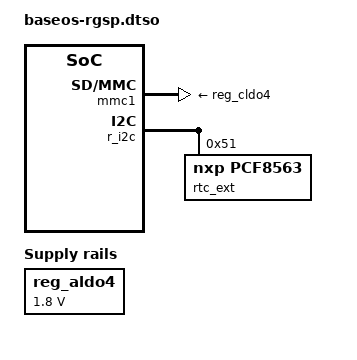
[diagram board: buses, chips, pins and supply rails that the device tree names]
// SPDX-License-Identifier: (GPL-2.0-only OR BSD-2-Clause)
/* The RG SP shares the RG28XX power chip and audio wiring. */
#include "baseos-rg28xx.dtso"

&battery {
    charge-full-design-microamp-hours = <3500000>;
};

&reg_aldo4 {
    regulator-min-microvolt = <1800000>;
    regulator-max-microvolt = <1800000>;
};

&axp717 {
    regulators {
        reg_cldo4: cldo4 {
            regulator-name = "vcc-radio";
            regulator-min-microvolt = <3300000>;
            regulator-max-microvolt = <3300000>;
            /* Bluetooth shares this rail with Wi-Fi. */
            regulator-always-on;
            regulator-boot-on;
        };
        reg_aldo1: aldo1 {
            regulator-name = "tf2-io";
            regulator-min-microvolt = <3300000>;
            regulator-max-microvolt = <3300000>;
        };
    };
};

&mmc1 {
    vmmc-supply = <&reg_cldo4>;
    vqmmc-supply = <&reg_aldo4>;
};

&mmc2 {
    vqmmc-supply = <&reg_aldo1>;
};

&pio {
    vcc-pg-supply = <&reg_aldo4>;
};

&r_i2c {
    #address-cells = <1>;
    #size-cells = <0>;
    rtc_ext: rtc@51 {
        compatible = "nxp,pcf8563";
        reg = <0x51>;
    };
};


